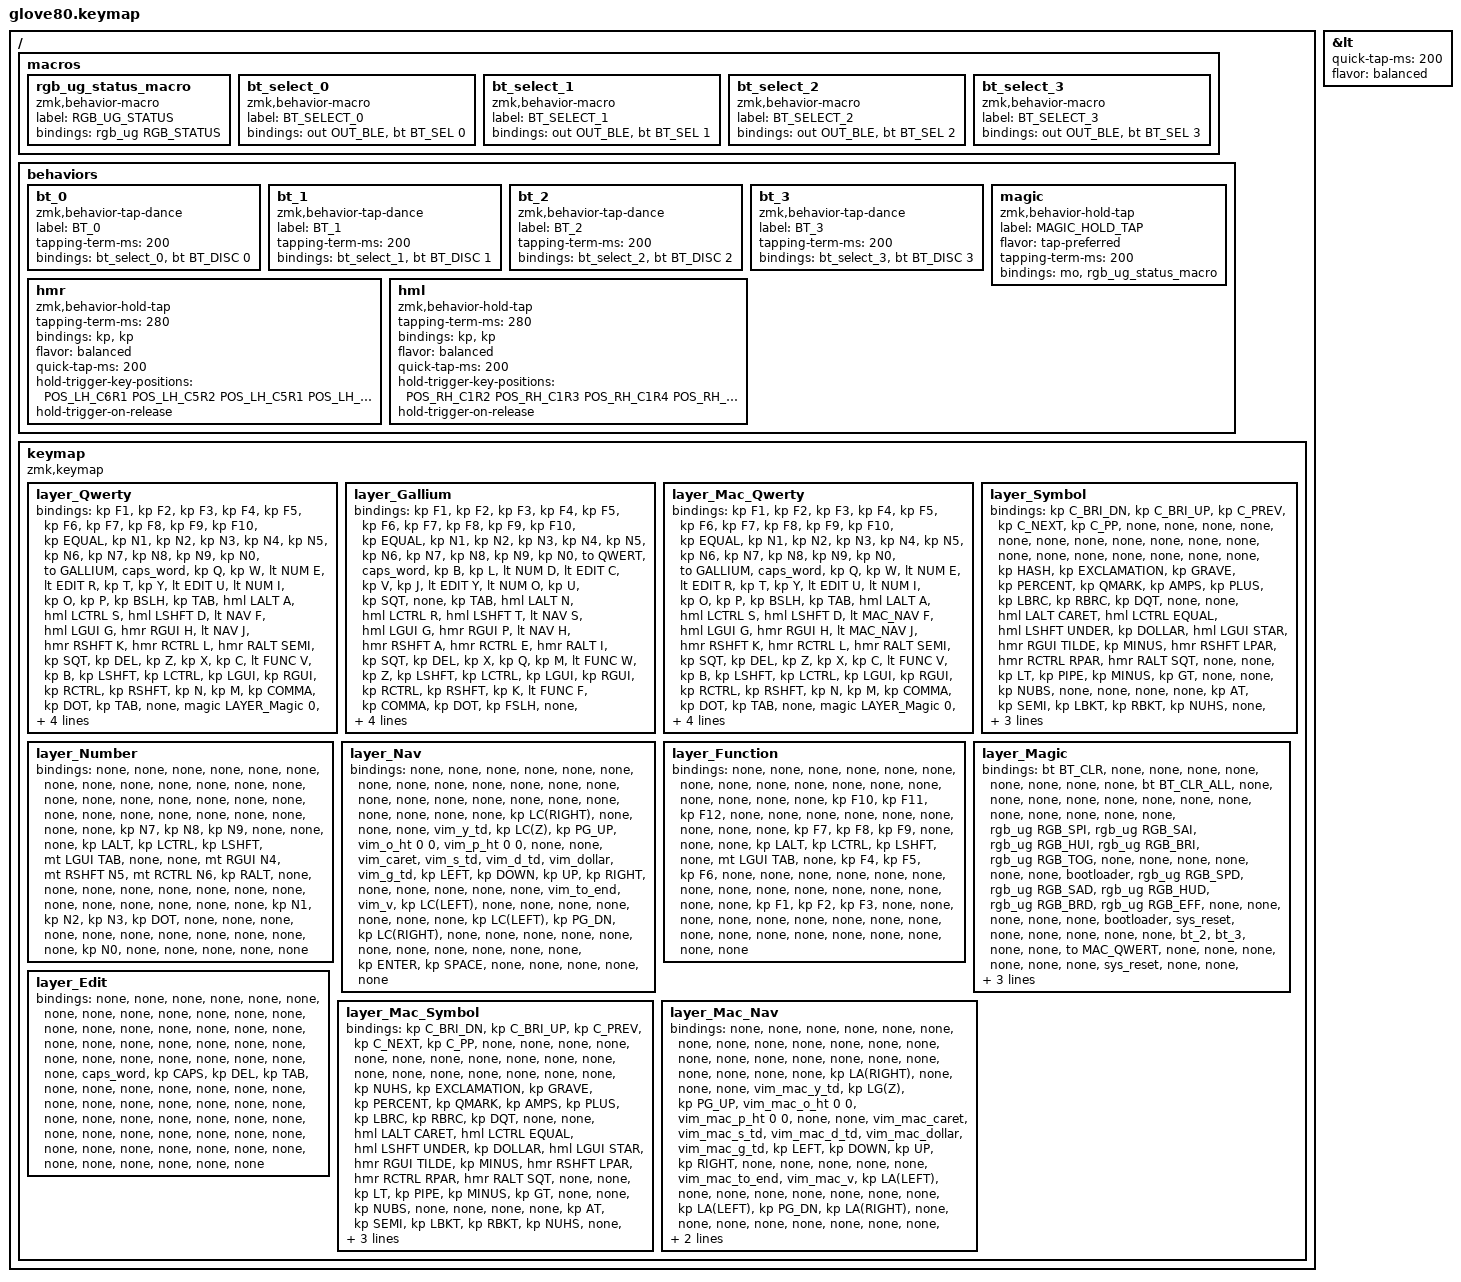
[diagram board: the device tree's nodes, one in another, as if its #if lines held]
#include <behaviors.dtsi>
/* Include all behavior includes needed */
#include <dt-bindings/zmk/outputs.h>
#include <dt-bindings/zmk/keys.h>
#include <dt-bindings/zmk/bt.h>
#include <dt-bindings/zmk/rgb.h>

/* Helper Macros, based on https://github.com/urob/zmk-helpers/ */

#pragma once

#define ZMK_HELPER_STRINGIFY(x) #x

// Preprocessor mechanism to overload macros, cf. https://stackoverflow.com/a/27051616/6114651
#define VARGS_(_10, _9, _8, _7, _6, _5, _4, _3, _2, _1, N, ...) N
#define VARGS(...) VARGS_(__VA_ARGS__, 10, 9, 8, 7, 6, 5, 4, 3, 2, 1, 0)
#define CONCAT_(a, b) a##b
#define CONCAT(a, b) CONCAT_(a, b)

#define ZMK_BEHAVIOR_CORE_tap_dance  \
    compatible = "zmk,behavior-tap-dance"; \
    #binding-cells = <0>

#define ZMK_BEHAVIOR(name, type, ...) \
    name: name { \
        ZMK_BEHAVIOR_CORE_ ## type; \
        __VA_ARGS__ \
    };

#define ZMK_TAP_DANCE(name, ...) \
    ZMK_BEHAVIOR(name, tap_dance, __VA_ARGS__)

#define ZMK_TD_LAYER(name, layer) \
    ZMK_TAP_DANCE(name, \
        tapping-term-ms = <200>; \
        bindings = <&mo layer>, <&to layer>; \
)

/* Automatically generated layer name defines */
#define QWERT 0
#define GALLIUM 1
#define MAC_QWERT 2
#define SYM 3
#define NUM 4
#define NAV 5
#define FUNC 6
#define LAYER_Magic 7
#define EDIT 8
#define MAC_SYM 9
#define MAC_NAV 10

/* Custom Device-tree */


/* Input Listeners */

/ {
    macros {
        rgb_ug_status_macro: rgb_ug_status_macro {
            label = "RGB_UG_STATUS";
            compatible = "zmk,behavior-macro";
            #binding-cells = <0>;
            bindings
                = <&rgb_ug RGB_STATUS>;
        };
    };
};


/ {
#ifdef BT_DISC_CMD
    behaviors {
        bt_0: bt_0 {
            compatible = "zmk,behavior-tap-dance";
            label = "BT_0";
            #binding-cells = <0>;
            tapping-term-ms = <200>;
            bindings = <&bt_select_0>, <&bt BT_DISC 0>;
        };
        bt_1: bt_1 {
            compatible = "zmk,behavior-tap-dance";
            label = "BT_1";
            #binding-cells = <0>;
            tapping-term-ms = <200>;
            bindings = <&bt_select_1>, <&bt BT_DISC 1>;
        };
        bt_2: bt_2 {
            compatible = "zmk,behavior-tap-dance";
            label = "BT_2";
            #binding-cells = <0>;
            tapping-term-ms = <200>;
            bindings = <&bt_select_2>, <&bt BT_DISC 2>;
        };
        bt_3: bt_3 {
            compatible = "zmk,behavior-tap-dance";
            label = "BT_3";
            #binding-cells = <0>;
            tapping-term-ms = <200>;
            bindings = <&bt_select_3>, <&bt BT_DISC 3>;
        };
    };
    macros {
        bt_select_0: bt_select_0 {
            label = "BT_SELECT_0";
            compatible = "zmk,behavior-macro";
            #binding-cells = <0>;
            bindings
                = <&out OUT_BLE>,
                  <&bt BT_SEL 0>;
        };
        bt_select_1: bt_select_1 {
            label = "BT_SELECT_1";
            compatible = "zmk,behavior-macro";
            #binding-cells = <0>;
            bindings
                = <&out OUT_BLE>,
                  <&bt BT_SEL 1>;
        };
        bt_select_2: bt_select_2 {
            label = "BT_SELECT_2";
            compatible = "zmk,behavior-macro";
            #binding-cells = <0>;
            bindings
                = <&out OUT_BLE>,
                  <&bt BT_SEL 2>;
        };
        bt_select_3: bt_select_3 {
            label = "BT_SELECT_3";
            compatible = "zmk,behavior-macro";
            #binding-cells = <0>;
            bindings
                = <&out OUT_BLE>,
                  <&bt BT_SEL 3>;
        };
    };
#else
    macros {
        bt_0: bt_0 {
            label = "BT_0";
            compatible = "zmk,behavior-macro";
            #binding-cells = <0>;
            bindings
                = <&out OUT_BLE>,
                  <&bt BT_SEL 0>;
        };
        bt_1: bt_1 {
            label = "BT_1";
            compatible = "zmk,behavior-macro";
            #binding-cells = <0>;
            bindings
                = <&out OUT_BLE>,
                  <&bt BT_SEL 1>;
        };
        bt_2: bt_2 {
            label = "BT_2";
            compatible = "zmk,behavior-macro";
            #binding-cells = <0>;
            bindings
                = <&out OUT_BLE>,
                  <&bt BT_SEL 2>;
        };
        bt_3: bt_3 {
            label = "BT_3";
            compatible = "zmk,behavior-macro";
            #binding-cells = <0>;
            bindings
                = <&out OUT_BLE>,
                  <&bt BT_SEL 3>;
        };
    };
#endif
};

/ {
    behaviors {
        magic: magic {
            compatible = "zmk,behavior-hold-tap";
            label = "MAGIC_HOLD_TAP";
            #binding-cells = <2>;
            flavor = "tap-preferred";
            tapping-term-ms = <200>;
            bindings = <&mo>, <&rgb_ug_status_macro>;
        };
    };
};


/* Key positions */

#define POS_LH_C6R1 0
#define POS_LH_C5R1 1
#define POS_LH_C4R1 2
#define POS_LH_C3R1 3
#define POS_LH_C2R1 4
#define POS_RH_C2R1 5
#define POS_RH_C3R1 6
#define POS_RH_C4R1 7
#define POS_RH_C5R1 8
#define POS_RH_C6R1 9
#define POS_LH_C6R2 10
#define POS_LH_C5R2 11
#define POS_LH_C4R2 12
#define POS_LH_C3R2 13
#define POS_LH_C2R2 14
#define POS_LH_C1R2 15
#define POS_RH_C1R2 16
#define POS_RH_C2R2 17
#define POS_RH_C3R2 18
#define POS_RH_C4R2 19
#define POS_RH_C5R2 20
#define POS_RH_C6R2 21
#define POS_LH_C6R3 22
#define POS_LH_C5R3 23
#define POS_LH_C4R3 24
#define POS_LH_C3R3 25
#define POS_LH_C2R3 26
#define POS_LH_C1R3 27
#define POS_RH_C1R3 28
#define POS_RH_C2R3 29
#define POS_RH_C3R3 30
#define POS_RH_C4R3 31
#define POS_RH_C5R3 32
#define POS_RH_C6R3 33
#define POS_LH_C6R4 34
#define POS_LH_C5R4 35
#define POS_LH_C4R4 36
#define POS_LH_C3R4 37
#define POS_LH_C2R4 38
#define POS_LH_C1R4 39
#define POS_RH_C1R4 40
#define POS_RH_C2R4 41
#define POS_RH_C3R4 42
#define POS_RH_C4R4 43
#define POS_RH_C5R4 44
#define POS_RH_C6R4 45
#define POS_LH_C6R5 46
#define POS_LH_C5R5 47
#define POS_LH_C4R5 48
#define POS_LH_C3R5 49
#define POS_LH_C2R5 50
#define POS_LH_C1R5 51
#define POS_LH_T1 52
#define POS_LH_T2 53
#define POS_LH_T3 54
#define POS_RH_T3 55
#define POS_RH_T2 56
#define POS_RH_T1 57
#define POS_RH_C1R5 58
#define POS_RH_C2R5 59
#define POS_RH_C3R5 60
#define POS_RH_C4R5 61
#define POS_RH_C5R5 62
#define POS_RH_C6R5 63
#define POS_LH_C6R6 64
#define POS_LH_C5R6 65
#define POS_LH_C4R6 66
#define POS_LH_C3R6 67
#define POS_LH_C2R6 68
#define POS_LH_T4 69
#define POS_LH_T5 70
#define POS_LH_T6 71
#define POS_RH_T6 72
#define POS_RH_T5 73
#define POS_RH_T4 74
#define POS_RH_C2R6 75
#define POS_RH_C3R6 76
#define POS_RH_C4R6 77
#define POS_RH_C5R6 78
#define POS_RH_C6R6 79

&lt {
    quick-tap-ms = <200>;
    flavor = "balanced";
};

/* Custom Defined Behaviors */
/ {

};

/* Generated input processors */


/* Automatically generated macro definitions */
/ {
    macros {

    };
};

/* Automatically generated behavior definitions */
/ {
    behaviors {

        // Right-hand HRMs
        hmr: hmr {
            compatible = "zmk,behavior-hold-tap";
            #binding-cells = <2>;
            tapping-term-ms = <280>;
            bindings = <&kp>, <&kp>;
            flavor = "balanced";
            quick-tap-ms = <200>;
            hold-trigger-key-positions = <POS_LH_C6R1 POS_LH_C5R2 POS_LH_C5R1 POS_LH_C4R2 POS_LH_C4R1 POS_LH_C4R3 POS_LH_C4R4 POS_LH_C4R6 POS_LH_C5R6 POS_LH_C5R5 POS_LH_C6R5 POS_LH_C6R6 POS_LH_C6R4 POS_LH_C5R4 POS_LH_C6R2 POS_LH_C5R3 POS_LH_C6R3 POS_LH_C4R5 POS_LH_C2R6 POS_LH_C2R5 POS_LH_C1R5 POS_LH_C2R4 POS_LH_C1R4 POS_LH_C3R4 POS_LH_C3R1 POS_LH_C2R1 POS_LH_C2R3 POS_LH_C1R3 POS_LH_C1R2 POS_LH_C2R2 POS_LH_C3R2 POS_LH_C3R3 POS_LH_C3R5 POS_LH_C3R6 POS_LH_T4 POS_LH_T6 POS_LH_T1 POS_LH_T5 POS_LH_T2 POS_LH_T3 POS_RH_T3 POS_RH_T1 POS_RH_T5 POS_RH_T2 POS_RH_T6 POS_RH_T4>;
            hold-trigger-on-release;
        };

        // Left-hand HRMs
        hml: hml {
            compatible = "zmk,behavior-hold-tap";
            #binding-cells = <2>;
            tapping-term-ms = <280>;
            bindings = <&kp>, <&kp>;
            flavor = "balanced";
            quick-tap-ms = <200>;
            hold-trigger-key-positions = <POS_RH_C1R2 POS_RH_C1R3 POS_RH_C1R4 POS_RH_C2R6 POS_RH_C1R5 POS_RH_C2R5 POS_RH_C2R1 POS_RH_C2R2 POS_RH_C2R3 POS_RH_C2R4 POS_RH_C3R4 POS_RH_C3R3 POS_RH_C3R2 POS_RH_C3R1 POS_RH_C4R1 POS_RH_C4R2 POS_RH_C4R3 POS_RH_C4R4 POS_RH_C4R5 POS_RH_C4R6 POS_RH_C3R6 POS_RH_C3R5 POS_RH_C5R6 POS_RH_C6R6 POS_RH_C6R5 POS_RH_C5R5 POS_RH_C5R4 POS_RH_C6R4 POS_RH_C6R3 POS_RH_C5R3 POS_RH_C5R2 POS_RH_C6R2 POS_RH_C6R1 POS_RH_C5R1 POS_RH_T3 POS_RH_T6 POS_RH_T5 POS_RH_T4 POS_RH_T1 POS_RH_T2 POS_LH_T3 POS_LH_T2 POS_LH_T6 POS_LH_T5 POS_LH_T4 POS_LH_T1>;
            hold-trigger-on-release;
        };
    };
};

#include "vim_macros.dtsi"

/* Automatically generated combos definitions */


/ {
    keymap {
        compatible = "zmk,keymap";


        layer_Qwerty {
            bindings = <
//    ┌────────────────────────┬─────────────┬─────────────┬─────────────┬───────────┐                                                                                                          ┌───────────┬─────────────┬─────────────┬─────────────┬────────────┐
//    │           f1           │     f2      │     f3      │     f4      │    f5     │                                                                                                          │    f6     │     f7      │     f8      │     f9      │    f10     │
//    ├────────────────────────┼─────────────┼─────────────┼─────────────┼───────────┼─────────────┐                                                                              ┌─────────────┼───────────┼─────────────┼─────────────┼─────────────┼────────────┤
//    │           =            │      1      │      2      │      3      │     4     │      5      │                                                                              │      6      │     7     │      8      │      9      │      0      │ to GALLIUM │
//    ├────────────────────────┼─────────────┼─────────────┼─────────────┼───────────┼─────────────┤                                                                              ├─────────────┼───────────┼─────────────┼─────────────┼─────────────┼────────────┤
//    │         capsw          │      Q      │      W      │  lt NUM E   │ lt EDIT R │      T      │                                                                              │      Y      │ lt EDIT U │  lt NUM I   │      O      │      P      │     \      │
//    ├────────────────────────┼─────────────┼─────────────┼─────────────┼───────────┼─────────────┤                                                                              ├─────────────┼───────────┼─────────────┼─────────────┼─────────────┼────────────┤
//    │          tab           │ &hml lalt A │ &hml lctl S │ &hml lsft D │ lt NAV F  │ &hml lgui G │                                                                              │ &hmr rgui H │ lt NAV J  │ &hmr rsft K │ &hmr rctl L │ &hmr ralt ; │     '      │
//    ├────────────────────────┼─────────────┼─────────────┼─────────────┼───────────┼─────────────┤   ┌─────────────┬────────────┬──────┐   ┌──────┬────────────┬────────────┐   ├─────────────┼───────────┼─────────────┼─────────────┼─────────────┼────────────┤
//    │          del           │      Z      │      X      │      C      │ lt FUNC V │      B      │   │    lsft     │    lctl    │ lgui │   │ rgui │    rctl    │    rsft    │   │      N      │     M     │      ,      │      .      │     tab     │            │
//    ├────────────────────────┼─────────────┼─────────────┼─────────────┼───────────┼─────────────┘   ├─────────────┼────────────┼──────┤   ├──────┼────────────┼────────────┤   └─────────────┼───────────┼─────────────┼─────────────┼─────────────┼────────────┤
//    │ &magic laltYER_Magic 0 │             │             │             │           │                 │ lt SYM bspc │ lt NUM esc │ del  │   │ ralt │ lt NUM ent │ lt SYM spc │                 │   left    │    down     │     up      │    rght     │    pscr    │
//    └────────────────────────┴─────────────┴─────────────┴─────────────┴───────────┘                 └─────────────┴────────────┴──────┘   └──────┴────────────┴────────────┘                 └───────────┴─────────────┴─────────────┴─────────────┴────────────┘
  &kp F1                 &kp F2        &kp F3         &kp F4         &kp F5                                                                                                                                &kp F6       &kp F7         &kp F8         &kp F9           &kp F10
  &kp EQUAL              &kp N1        &kp N2         &kp N3         &kp N4       &kp N5                                                                                                     &kp N6        &kp N7       &kp N8         &kp N9         &kp N0           &to GALLIUM
  &caps_word             &kp Q         &kp W          &lt NUM E      &lt EDIT R   &kp T                                                                                                      &kp Y         &lt EDIT U   &lt NUM I      &kp O          &kp P            &kp BSLH
  &kp TAB                &hml LALT A   &hml LCTRL S   &hml LSHFT D   &lt NAV F    &hml LGUI G                                                                                                &hmr RGUI H   &lt NAV J    &hmr RSHFT K   &hmr RCTRL L   &hmr RALT SEMI   &kp SQT
  &kp DEL                &kp Z         &kp X          &kp C          &lt FUNC V   &kp B             &kp LSHFT      &kp LCTRL     &kp LGUI       &kp RGUI   &kp RCTRL     &kp RSHFT           &kp N         &kp M        &kp COMMA      &kp DOT        &kp TAB          &none
  &magic LAYER_Magic 0   &none         &none          &none          &none                          &lt SYM BSPC   &lt NUM ESC   &kp DEL        &kp RALT   &lt NUM RET   &lt SYM SPACE                     &kp LEFT     &kp DOWN       &kp UP         &kp RIGHT        &kp PSCRN
            >;
        };



        layer_Gallium {
            bindings = <
//    ┌────────────────────────┬─────────────┬─────────────┬─────────────┬───────────┐                                                                                                          ┌───────────┬─────────────┬─────────────┬─────────────┬──────────┐
//    │           f1           │     f2      │     f3      │     f4      │    f5     │                                                                                                          │    f6     │     f7      │     f8      │     f9      │   f10    │
//    ├────────────────────────┼─────────────┼─────────────┼─────────────┼───────────┼─────────────┐                                                                              ┌─────────────┼───────────┼─────────────┼─────────────┼─────────────┼──────────┤
//    │           =            │      1      │      2      │      3      │     4     │      5      │                                                                              │      6      │     7     │      8      │      9      │      0      │ to QWERT │
//    ├────────────────────────┼─────────────┼─────────────┼─────────────┼───────────┼─────────────┤                                                                              ├─────────────┼───────────┼─────────────┼─────────────┼─────────────┼──────────┤
//    │         capsw          │      B      │      L      │  lt NUM D   │ lt EDIT C │      V      │                                                                              │      J      │ lt EDIT Y │  lt NUM O   │      U      │      '      │          │
//    ├────────────────────────┼─────────────┼─────────────┼─────────────┼───────────┼─────────────┤                                                                              ├─────────────┼───────────┼─────────────┼─────────────┼─────────────┼──────────┤
//    │          tab           │ &hml lalt N │ &hml lctl R │ &hml lsft T │ lt NAV S  │ &hml lgui G │                                                                              │ &hmr rgui P │ lt NAV H  │ &hmr rsft A │ &hmr rctl E │ &hmr ralt I │    '     │
//    ├────────────────────────┼─────────────┼─────────────┼─────────────┼───────────┼─────────────┤   ┌─────────────┬────────────┬──────┐   ┌──────┬────────────┬────────────┐   ├─────────────┼───────────┼─────────────┼─────────────┼─────────────┼──────────┤
//    │          del           │      X      │      Q      │      M      │ lt FUNC W │      Z      │   │    lsft     │    lctl    │ lgui │   │ rgui │    rctl    │    rsft    │   │      K      │ lt FUNC F │      ,      │      .      │      /      │          │
//    ├────────────────────────┼─────────────┼─────────────┼─────────────┼───────────┼─────────────┘   ├─────────────┼────────────┼──────┤   ├──────┼────────────┼────────────┤   └─────────────┼───────────┼─────────────┼─────────────┼─────────────┼──────────┤
//    │ &magic laltYER_Magic 0 │             │             │             │           │                 │ lt SYM bspc │ lt NUM esc │ del  │   │ ralt │ lt NUM ent │ lt SYM spc │                 │   left    │    down     │     up      │    rght     │   pscr   │
//    └────────────────────────┴─────────────┴─────────────┴─────────────┴───────────┘                 └─────────────┴────────────┴──────┘   └──────┴────────────┴────────────┘                 └───────────┴─────────────┴─────────────┴─────────────┴──────────┘
  &kp F1                 &kp F2        &kp F3         &kp F4         &kp F5                                                                                                                                &kp F6       &kp F7         &kp F8         &kp F9        &kp F10
  &kp EQUAL              &kp N1        &kp N2         &kp N3         &kp N4       &kp N5                                                                                                     &kp N6        &kp N7       &kp N8         &kp N9         &kp N0        &to QWERT
  &caps_word             &kp B         &kp L          &lt NUM D      &lt EDIT C   &kp V                                                                                                      &kp J         &lt EDIT Y   &lt NUM O      &kp U          &kp SQT       &none
  &kp TAB                &hml LALT N   &hml LCTRL R   &hml LSHFT T   &lt NAV S    &hml LGUI G                                                                                                &hmr RGUI P   &lt NAV H    &hmr RSHFT A   &hmr RCTRL E   &hmr RALT I   &kp SQT
  &kp DEL                &kp X         &kp Q          &kp M          &lt FUNC W   &kp Z             &kp LSHFT      &kp LCTRL     &kp LGUI       &kp RGUI   &kp RCTRL     &kp RSHFT           &kp K         &lt FUNC F   &kp COMMA      &kp DOT        &kp FSLH      &none
  &magic LAYER_Magic 0   &none         &none          &none          &none                          &lt SYM BSPC   &lt NUM ESC   &kp DEL        &kp RALT   &lt NUM RET   &lt SYM SPACE                     &kp LEFT     &kp DOWN       &kp UP         &kp RIGHT     &kp PSCRN
            >;
        };

        layer_Mac_Qwerty {
            bindings = <
//    ┌────────────────────────┬─────────────┬─────────────┬─────────────┬──────────────┐                                                                                                                  ┌──────────────┬─────────────┬─────────────┬─────────────┬────────────┐
//    │           f1           │     f2      │     f3      │     f4      │      f5      │                                                                                                                  │      f6      │     f7      │     f8      │     f9      │    f10     │
//    ├────────────────────────┼─────────────┼─────────────┼─────────────┼──────────────┼─────────────┐                                                                                      ┌─────────────┼──────────────┼─────────────┼─────────────┼─────────────┼────────────┤
//    │           =            │      1      │      2      │      3      │      4       │      5      │                                                                                      │      6      │      7       │      8      │      9      │      0      │ to GALLIUM │
//    ├────────────────────────┼─────────────┼─────────────┼─────────────┼──────────────┼─────────────┤                                                                                      ├─────────────┼──────────────┼─────────────┼─────────────┼─────────────┼────────────┤
//    │         capsw          │      Q      │      W      │  lt NUM E   │  lt EDIT R   │      T      │                                                                                      │      Y      │  lt EDIT U   │  lt NUM I   │      O      │      P      │     \      │
//    ├────────────────────────┼─────────────┼─────────────┼─────────────┼──────────────┼─────────────┤                                                                                      ├─────────────┼──────────────┼─────────────┼─────────────┼─────────────┼────────────┤
//    │          tab           │ &hml lalt A │ &hml lctl S │ &hml lsft D │ lt MAC_NAV F │ &hml lgui G │                                                                                      │ &hmr rgui H │ lt MAC_NAV J │ &hmr rsft K │ &hmr rctl L │ &hmr ralt ; │     '      │
//    ├────────────────────────┼─────────────┼─────────────┼─────────────┼──────────────┼─────────────┤   ┌─────────────────┬────────────┬──────┐   ┌──────┬────────────┬────────────────┐   ├─────────────┼──────────────┼─────────────┼─────────────┼─────────────┼────────────┤
//    │          del           │      Z      │      X      │      C      │  lt FUNC V   │      B      │   │      lsft       │    lctl    │ lgui │   │ rgui │    rctl    │      rsft      │   │      N      │      M       │      ,      │      .      │     tab     │            │
//    ├────────────────────────┼─────────────┼─────────────┼─────────────┼──────────────┼─────────────┘   ├─────────────────┼────────────┼──────┤   ├──────┼────────────┼────────────────┤   └─────────────┼──────────────┼─────────────┼─────────────┼─────────────┼────────────┤
//    │ &magic laltYER_Magic 0 │             │             │             │              │                 │ lt MAC_SYM bspc │ lt NUM esc │ del  │   │ ralt │ lt NUM ent │ lt MAC_SYM spc │                 │     left     │    down     │     up      │    rght     │    pscr    │
//    └────────────────────────┴─────────────┴─────────────┴─────────────┴──────────────┘                 └─────────────────┴────────────┴──────┘   └──────┴────────────┴────────────────┘                 └──────────────┴─────────────┴─────────────┴─────────────┴────────────┘
  &kp F1                 &kp F2        &kp F3         &kp F4         &kp F5                                                                                                                                           &kp F6          &kp F7         &kp F8         &kp F9           &kp F10
  &kp EQUAL              &kp N1        &kp N2         &kp N3         &kp N4          &kp N5                                                                                                             &kp N6        &kp N7          &kp N8         &kp N9         &kp N0           &to GALLIUM
  &caps_word             &kp Q         &kp W          &lt NUM E      &lt EDIT R      &kp T                                                                                                              &kp Y         &lt EDIT U      &lt NUM I      &kp O          &kp P            &kp BSLH
  &kp TAB                &hml LALT A   &hml LCTRL S   &hml LSHFT D   &lt MAC_NAV F   &hml LGUI G                                                                                                        &hmr RGUI H   &lt MAC_NAV J   &hmr RSHFT K   &hmr RCTRL L   &hmr RALT SEMI   &kp SQT
  &kp DEL                &kp Z         &kp X          &kp C          &lt FUNC V      &kp B             &kp LSHFT          &kp LCTRL     &kp LGUI       &kp RGUI   &kp RCTRL     &kp RSHFT               &kp N         &kp M           &kp COMMA      &kp DOT        &kp TAB          &none
  &magic LAYER_Magic 0   &none         &none          &none          &none                             &lt MAC_SYM BSPC   &lt NUM ESC   &kp DEL        &kp RALT   &lt NUM RET   &lt MAC_SYM SPACE                     &kp LEFT        &kp DOWN       &kp UP         &kp RIGHT        &kp PSCRN
            >;
        };

        layer_Symbol {
            bindings = <
//    ┌──────┬─────────────┬─────────────┬─────────────┬──────┐                                                                            ┌─────┬─────────────┬─────────────┬─────────────┬─────┐
//    │ bri- │    bri+     │    prev     │    next     │ play │                                                                            │     │             │             │             │     │
//    ├──────┼─────────────┼─────────────┼─────────────┼──────┼─────────────┐                                                ┌─────────────┼─────┼─────────────┼─────────────┼─────────────┼─────┤
//    │      │             │             │             │      │             │                                                │             │     │             │             │             │     │
//    ├──────┼─────────────┼─────────────┼─────────────┼──────┼─────────────┤                                                ├─────────────┼─────┼─────────────┼─────────────┼─────────────┼─────┤
//    │      │      #      │      !      │      `      │  %   │      ?      │                                                │      &      │  +  │      {      │      }      │      "      │     │
//    ├──────┼─────────────┼─────────────┼─────────────┼──────┼─────────────┤                                                ├─────────────┼─────┼─────────────┼─────────────┼─────────────┼─────┤
//    │      │ &hml lalt ^ │ &hml lctl = │ &hml lsft _ │  $   │ &hml lgui * │                                                │ &hmr rgui ~ │  -  │ &hmr rsft ( │ &hmr rctl ) │ &hmr ralt ' │     │
//    ├──────┼─────────────┼─────────────┼─────────────┼──────┼─────────────┤   ┌─────┬──────┬─────┐   ┌─────┬─────┬─────┐   ├─────────────┼─────┼─────────────┼─────────────┼─────────────┼─────┤
//    │      │      <      │      |      │      -      │  >   │             │   │     │ iso\ │     │   │     │     │     │   │      @      │  ;  │      [      │      ]      │    iso#     │     │
//    ├──────┼─────────────┼─────────────┼─────────────┼──────┼─────────────┘   ├─────┼──────┼─────┤   ├─────┼─────┼─────┤   └─────────────┼─────┼─────────────┼─────────────┼─────────────┼─────┤
//    │      │             │             │             │      │                 │  /  │  \   │     │   │     │ spc │  :  │                 │     │             │             │             │     │
//    └──────┴─────────────┴─────────────┴─────────────┴──────┘                 └─────┴──────┴─────┘   └─────┴─────┴─────┘                 └─────┴─────────────┴─────────────┴─────────────┴─────┘
  &kp C_BRI_DN   &kp C_BRI_UP      &kp C_PREV         &kp C_NEXT         &kp C_PP                                                                                                                   &none       &none             &none             &none           &none
  &none          &none             &none              &none              &none         &none                                                                                      &none             &none       &none             &none             &none           &none
  &none          &kp HASH          &kp EXCLAMATION    &kp GRAVE          &kp PERCENT   &kp QMARK                                                                                  &kp AMPS          &kp PLUS    &kp LBRC          &kp RBRC          &kp DQT         &none
  &none          &hml LALT CARET   &hml LCTRL EQUAL   &hml LSHFT UNDER   &kp DOLLAR    &hml LGUI STAR                                                                             &hmr RGUI TILDE   &kp MINUS   &hmr RSHFT LPAR   &hmr RCTRL RPAR   &hmr RALT SQT   &none
  &none          &kp LT            &kp PIPE           &kp MINUS          &kp GT        &none                &none      &kp NUBS   &none       &none   &none       &none           &kp AT            &kp SEMI    &kp LBKT          &kp RBKT          &kp NUHS        &none
  &none          &none             &none              &none              &none                              &kp FSLH   &kp BSLH   &none       &none   &kp SPACE   &kp COLON                         &none       &none             &none             &none           &none
            >;
        };





        layer_Number {
            bindings = <
//    ┌─────┬──────┬──────┬──────┬─────────────┐                                                           ┌───────────┬───────────┬───────────┬──────┬─────┐
//    │     │      │      │      │             │                                                           │           │           │           │      │     │
//    ├─────┼──────┼──────┼──────┼─────────────┼─────┐                                               ┌─────┼───────────┼───────────┼───────────┼──────┼─────┤
//    │     │      │      │      │             │     │                                               │     │           │           │           │      │     │
//    ├─────┼──────┼──────┼──────┼─────────────┼─────┤                                               ├─────┼───────────┼───────────┼───────────┼──────┼─────┤
//    │     │      │      │      │             │     │                                               │     │     7     │     8     │     9     │      │     │
//    ├─────┼──────┼──────┼──────┼─────────────┼─────┤                                               ├─────┼───────────┼───────────┼───────────┼──────┼─────┤
//    │     │ lalt │ lctl │ lsft │ mt lgui tab │     │                                               │     │ mt rgui 4 │ mt rsft 5 │ mt rctl 6 │ ralt │     │
//    ├─────┼──────┼──────┼──────┼─────────────┼─────┤   ┌─────┬─────┬─────┐   ┌─────┬─────┬─────┐   ├─────┼───────────┼───────────┼───────────┼──────┼─────┤
//    │     │      │      │      │             │     │   │     │     │     │   │     │     │     │   │     │     1     │     2     │     3     │  .   │     │
//    ├─────┼──────┼──────┼──────┼─────────────┼─────┘   ├─────┼─────┼─────┤   ├─────┼─────┼─────┤   └─────┼───────────┼───────────┼───────────┼──────┼─────┤
//    │     │      │      │      │             │         │     │     │     │   │     │     │  0  │         │           │           │           │      │     │
//    └─────┴──────┴──────┴──────┴─────────────┘         └─────┴─────┴─────┘   └─────┴─────┴─────┘         └───────────┴───────────┴───────────┴──────┴─────┘
  &none   &none      &none       &none       &none                                                                                       &none         &none          &none          &none      &none
  &none   &none      &none       &none       &none          &none                                                                &none   &none         &none          &none          &none      &none
  &none   &none      &none       &none       &none          &none                                                                &none   &kp N7        &kp N8         &kp N9         &none      &none
  &none   &kp LALT   &kp LCTRL   &kp LSHFT   &mt LGUI TAB   &none                                                                &none   &mt RGUI N4   &mt RSHFT N5   &mt RCTRL N6   &kp RALT   &none
  &none   &none      &none       &none       &none          &none       &none   &none   &none       &none   &none   &none        &none   &kp N1        &kp N2         &kp N3         &kp DOT    &none
  &none   &none      &none       &none       &none                      &none   &none   &none       &none   &none   &kp N0               &none         &none          &none          &none      &none
            >;
        };




        layer_Nav {
            bindings = <
//    ┌─────┬────────────┬────────────┬─────────────┬─────────────┐                                                                        ┌────────────┬──────┬───────────────┬───────────────┬─────┐
//    │     │            │            │             │             │                                                                        │            │      │               │               │     │
//    ├─────┼────────────┼────────────┼─────────────┼─────────────┼────────────┐                                               ┌───────────┼────────────┼──────┼───────────────┼───────────────┼─────┤
//    │     │            │            │             │             │            │                                               │           │            │      │               │               │     │
//    ├─────┼────────────┼────────────┼─────────────┼─────────────┼────────────┤                                               ├───────────┼────────────┼──────┼───────────────┼───────────────┼─────┤
//    │     │            │ lctl(rght) │             │             │            │                                               │ &vim_y_td │  lctl(Z)   │ pgup │ &vim_o_ht 0 0 │ &vim_p_ht 0 0 │     │
//    ├─────┼────────────┼────────────┼─────────────┼─────────────┼────────────┤                                               ├───────────┼────────────┼──────┼───────────────┼───────────────┼─────┤
//    │     │ &vim_caret │ &vim_s_td  │  &vim_d_td  │ &vim_dollar │ &vim_g_td  │                                               │   left    │    down    │  up  │     rght      │               │     │
//    ├─────┼────────────┼────────────┼─────────────┼─────────────┼────────────┤   ┌─────┬─────┬─────┐   ┌─────┬─────┬─────┐   ├───────────┼────────────┼──────┼───────────────┼───────────────┼─────┤
//    │     │            │            │ &vim_to_end │   &vim_v    │ lctl(left) │   │     │     │     │   │     │     │     │   │           │ lctl(left) │ pgdn │  lctl(rght)   │               │     │
//    ├─────┼────────────┼────────────┼─────────────┼─────────────┼────────────┘   ├─────┼─────┼─────┤   ├─────┼─────┼─────┤   └───────────┼────────────┼──────┼───────────────┼───────────────┼─────┤
//    │     │            │            │             │             │                │     │     │     │   │     │ ent │ spc │               │            │      │               │               │     │
//    └─────┴────────────┴────────────┴─────────────┴─────────────┘                └─────┴─────┴─────┘   └─────┴─────┴─────┘               └────────────┴──────┴───────────────┴───────────────┴─────┘
  &none   &none        &none           &none         &none                                                                                                        &none          &none       &none           &none           &none
  &none   &none        &none           &none         &none         &none                                                                              &none       &none          &none       &none           &none           &none
  &none   &none        &kp LC(RIGHT)   &none         &none         &none                                                                              &vim_y_td   &kp LC(Z)      &kp PG_UP   &vim_o_ht 0 0   &vim_p_ht 0 0   &none
  &none   &vim_caret   &vim_s_td       &vim_d_td     &vim_dollar   &vim_g_td                                                                          &kp LEFT    &kp DOWN       &kp UP      &kp RIGHT       &none           &none
  &none   &none        &none           &vim_to_end   &vim_v        &kp LC(LEFT)       &none   &none   &none       &none   &none       &none           &none       &kp LC(LEFT)   &kp PG_DN   &kp LC(RIGHT)   &none           &none
  &none   &none        &none           &none         &none                            &none   &none   &none       &none   &kp ENTER   &kp SPACE                   &none          &none       &none           &none           &none
            >;
        };




        layer_Function {
            bindings = <
//    ┌─────┬──────┬──────┬──────┬─────┐                                                                   ┌─────┬─────┬─────┬─────┬─────┐
//    │     │      │      │      │     │                                                                   │     │     │     │     │     │
//    ├─────┼──────┼──────┼──────┼─────┼─────────────┐                                               ┌─────┼─────┼─────┼─────┼─────┼─────┤
//    │     │      │      │      │     │             │                                               │     │ f10 │ f11 │ f12 │     │     │
//    ├─────┼──────┼──────┼──────┼─────┼─────────────┤                                               ├─────┼─────┼─────┼─────┼─────┼─────┤
//    │     │      │      │      │     │             │                                               │     │ f7  │ f8  │ f9  │     │     │
//    ├─────┼──────┼──────┼──────┼─────┼─────────────┤                                               ├─────┼─────┼─────┼─────┼─────┼─────┤
//    │     │ lalt │ lctl │ lsft │     │ mt lgui tab │                                               │     │ f4  │ f5  │ f6  │     │     │
//    ├─────┼──────┼──────┼──────┼─────┼─────────────┤   ┌─────┬─────┬─────┐   ┌─────┬─────┬─────┐   ├─────┼─────┼─────┼─────┼─────┼─────┤
//    │     │      │      │      │     │             │   │     │     │     │   │     │     │     │   │     │ f1  │ f2  │ f3  │     │     │
//    ├─────┼──────┼──────┼──────┼─────┼─────────────┘   ├─────┼─────┼─────┤   ├─────┼─────┼─────┤   └─────┼─────┼─────┼─────┼─────┼─────┤
//    │     │      │      │      │     │                 │     │     │     │   │     │     │     │         │     │     │     │     │     │
//    └─────┴──────┴──────┴──────┴─────┘                 └─────┴─────┴─────┘   └─────┴─────┴─────┘         └─────┴─────┴─────┴─────┴─────┘
  &none   &none      &none       &none       &none                                                                                      &none     &none     &none     &none   &none
  &none   &none      &none       &none       &none   &none                                                                      &none   &kp F10   &kp F11   &kp F12   &none   &none
  &none   &none      &none       &none       &none   &none                                                                      &none   &kp F7    &kp F8    &kp F9    &none   &none
  &none   &kp LALT   &kp LCTRL   &kp LSHFT   &none   &mt LGUI TAB                                                               &none   &kp F4    &kp F5    &kp F6    &none   &none
  &none   &none      &none       &none       &none   &none              &none   &none   &none       &none   &none   &none       &none   &kp F1    &kp F2    &kp F3    &none   &none
  &none   &none      &none       &none       &none                      &none   &none   &none       &none   &none   &none               &none     &none     &none     &none   &none
            >;
        };




        layer_Magic {
            bindings = <
//    ┌────────────┬─────────┬─────────┬─────────┬─────────┐                                                                                        ┌─────┬─────┬─────┬─────┬────────────┐
//    │   bt_clr   │         │         │         │         │                                                                                        │     │     │     │     │ bt_clr_ALL │
//    ├────────────┼─────────┼─────────┼─────────┼─────────┼─────────┐                                                                        ┌─────┼─────┼─────┼─────┼─────┼────────────┤
//    │            │         │         │         │         │         │                                                                        │     │     │     │     │     │            │
//    ├────────────┼─────────┼─────────┼─────────┼─────────┼─────────┤                                                                        ├─────┼─────┼─────┼─────┼─────┼────────────┤
//    │            │ ug_ sp+ │ ug_ sa+ │ ug_ hu+ │ ug_ br+ │ ug_ tog │                                                                        │     │     │     │     │     │            │
//    ├────────────┼─────────┼─────────┼─────────┼─────────┼─────────┤                                                                        ├─────┼─────┼─────┼─────┼─────┼────────────┤
//    │    boot    │ ug_ sp- │ ug_ sa- │ ug_ hu- │ ug_ br- │ ug_ eff │                                                                        │     │     │     │     │     │    boot    │
//    ├────────────┼─────────┼─────────┼─────────┼─────────┼─────────┤   ┌───────┬───────┬──────────┐   ┌─────┬──────────────┬────────────┐   ├─────┼─────┼─────┼─────┼─────┼────────────┤
//    │ &sys_reset │         │         │         │         │         │   │ &bt_2 │ &bt_3 │          │   │     │ to MAC_QWERT │            │   │     │     │     │     │     │ &sys_reset │
//    ├────────────┼─────────┼─────────┼─────────┼─────────┼─────────┘   ├───────┼───────┼──────────┤   ├─────┼──────────────┼────────────┤   └─────┼─────┼─────┼─────┼─────┼────────────┤
//    │            │         │         │         │         │             │ &bt_0 │ &bt_1 │ out_ usb │   │     │   to QWERT   │ to GALLIUM │         │     │     │     │     │            │
//    └────────────┴─────────┴─────────┴─────────┴─────────┘             └───────┴───────┴──────────┘   └─────┴──────────────┴────────────┘         └─────┴─────┴─────┴─────┴────────────┘
  &bt BT_CLR    &none             &none             &none             &none                                                                                                                        &none   &none   &none   &none   &bt BT_CLR_ALL
  &none         &none             &none             &none             &none             &none                                                                                              &none   &none   &none   &none   &none   &none
  &none         &rgb_ug RGB_SPI   &rgb_ug RGB_SAI   &rgb_ug RGB_HUI   &rgb_ug RGB_BRI   &rgb_ug RGB_TOG                                                                                    &none   &none   &none   &none   &none   &none
  &bootloader   &rgb_ug RGB_SPD   &rgb_ug RGB_SAD   &rgb_ug RGB_HUD   &rgb_ug RGB_BRD   &rgb_ug RGB_EFF                                                                                    &none   &none   &none   &none   &none   &bootloader
  &sys_reset    &none             &none             &none             &none             &none                 &bt_2   &bt_3   &none              &none   &to MAC_QWERT   &none             &none   &none   &none   &none   &none   &sys_reset
  &none         &none             &none             &none             &none                                   &bt_0   &bt_1   &out OUT_USB       &none   &to QWERT       &to GALLIUM               &none   &none   &none   &none   &none
            >;
        };

        layer_Edit {
            bindings = <
//    ┌─────┬───────┬──────┬─────┬─────┐                                                           ┌─────┬─────┬─────┬─────┬─────┐
//    │     │       │      │     │     │                                                           │     │     │     │     │     │
//    ├─────┼───────┼──────┼─────┼─────┼─────┐                                               ┌─────┼─────┼─────┼─────┼─────┼─────┤
//    │     │       │      │     │     │     │                                               │     │     │     │     │     │     │
//    ├─────┼───────┼──────┼─────┼─────┼─────┤                                               ├─────┼─────┼─────┼─────┼─────┼─────┤
//    │     │       │      │     │     │     │                                               │     │     │     │     │     │     │
//    ├─────┼───────┼──────┼─────┼─────┼─────┤                                               ├─────┼─────┼─────┼─────┼─────┼─────┤
//    │     │ capsw │ caps │ del │ tab │     │                                               │     │     │     │     │     │     │
//    ├─────┼───────┼──────┼─────┼─────┼─────┤   ┌─────┬─────┬─────┐   ┌─────┬─────┬─────┐   ├─────┼─────┼─────┼─────┼─────┼─────┤
//    │     │       │      │     │     │     │   │     │     │     │   │     │     │     │   │     │     │     │     │     │     │
//    ├─────┼───────┼──────┼─────┼─────┼─────┘   ├─────┼─────┼─────┤   ├─────┼─────┼─────┤   └─────┼─────┼─────┼─────┼─────┼─────┤
//    │     │       │      │     │     │         │     │     │     │   │     │     │     │         │     │     │     │     │     │
//    └─────┴───────┴──────┴─────┴─────┘         └─────┴─────┴─────┘   └─────┴─────┴─────┘         └─────┴─────┴─────┴─────┴─────┘
  &none   &none        &none      &none     &none                                                                                 &none   &none   &none   &none   &none
  &none   &none        &none      &none     &none     &none                                                               &none   &none   &none   &none   &none   &none
  &none   &none        &none      &none     &none     &none                                                               &none   &none   &none   &none   &none   &none
  &none   &caps_word   &kp CAPS   &kp DEL   &kp TAB   &none                                                               &none   &none   &none   &none   &none   &none
  &none   &none        &none      &none     &none     &none       &none   &none   &none       &none   &none   &none       &none   &none   &none   &none   &none   &none
  &none   &none        &none      &none     &none                 &none   &none   &none       &none   &none   &none               &none   &none   &none   &none   &none
            >;
        };


        layer_Mac_Symbol {
            bindings = <
//    ┌──────┬─────────────┬─────────────┬─────────────┬──────┐                                                                            ┌─────┬─────────────┬─────────────┬─────────────┬─────┐
//    │ bri- │    bri+     │    prev     │    next     │ play │                                                                            │     │             │             │             │     │
//    ├──────┼─────────────┼─────────────┼─────────────┼──────┼─────────────┐                                                ┌─────────────┼─────┼─────────────┼─────────────┼─────────────┼─────┤
//    │      │             │             │             │      │             │                                                │             │     │             │             │             │     │
//    ├──────┼─────────────┼─────────────┼─────────────┼──────┼─────────────┤                                                ├─────────────┼─────┼─────────────┼─────────────┼─────────────┼─────┤
//    │      │    iso#     │      !      │      `      │  %   │      ?      │                                                │      &      │  +  │      {      │      }      │      "      │     │
//    ├──────┼─────────────┼─────────────┼─────────────┼──────┼─────────────┤                                                ├─────────────┼─────┼─────────────┼─────────────┼─────────────┼─────┤
//    │      │ &hml lalt ^ │ &hml lctl = │ &hml lsft _ │  $   │ &hml lgui * │                                                │ &hmr rgui ~ │  -  │ &hmr rsft ( │ &hmr rctl ) │ &hmr ralt ' │     │
//    ├──────┼─────────────┼─────────────┼─────────────┼──────┼─────────────┤   ┌─────┬──────┬─────┐   ┌─────┬─────┬─────┐   ├─────────────┼─────┼─────────────┼─────────────┼─────────────┼─────┤
//    │      │      <      │      |      │      -      │  >   │             │   │     │ iso\ │     │   │     │     │     │   │      @      │  ;  │      [      │      ]      │    iso#     │     │
//    ├──────┼─────────────┼─────────────┼─────────────┼──────┼─────────────┘   ├─────┼──────┼─────┤   ├─────┼─────┼─────┤   └─────────────┼─────┼─────────────┼─────────────┼─────────────┼─────┤
//    │      │             │             │             │      │                 │  /  │  \   │     │   │     │ spc │  :  │                 │     │             │             │             │     │
//    └──────┴─────────────┴─────────────┴─────────────┴──────┘                 └─────┴──────┴─────┘   └─────┴─────┴─────┘                 └─────┴─────────────┴─────────────┴─────────────┴─────┘
  &kp C_BRI_DN   &kp C_BRI_UP      &kp C_PREV         &kp C_NEXT         &kp C_PP                                                                                                                   &none       &none             &none             &none           &none
  &none          &none             &none              &none              &none         &none                                                                                      &none             &none       &none             &none             &none           &none
  &none          &kp NUHS          &kp EXCLAMATION    &kp GRAVE          &kp PERCENT   &kp QMARK                                                                                  &kp AMPS          &kp PLUS    &kp LBRC          &kp RBRC          &kp DQT         &none
  &none          &hml LALT CARET   &hml LCTRL EQUAL   &hml LSHFT UNDER   &kp DOLLAR    &hml LGUI STAR                                                                             &hmr RGUI TILDE   &kp MINUS   &hmr RSHFT LPAR   &hmr RCTRL RPAR   &hmr RALT SQT   &none
  &none          &kp LT            &kp PIPE           &kp MINUS          &kp GT        &none                &none      &kp NUBS   &none       &none   &none       &none           &kp AT            &kp SEMI    &kp LBKT          &kp RBKT          &kp NUHS        &none
  &none          &none             &none              &none              &none                              &kp FSLH   &kp BSLH   &none       &none   &kp SPACE   &kp COLON                         &none       &none             &none             &none           &none
            >;
        };

        layer_Mac_Nav {
            bindings = <
//    ┌─────┬────────────────┬───────────────┬─────────────────┬─────────────────┐                                                                               ┌────────────┬──────┬───────────────────┬───────────────────┬─────┐
//    │     │                │               │                 │                 │                                                                               │            │      │                   │                   │     │
//    ├─────┼────────────────┼───────────────┼─────────────────┼─────────────────┼───────────────┐                                               ┌───────────────┼────────────┼──────┼───────────────────┼───────────────────┼─────┤
//    │     │                │               │                 │                 │               │                                               │               │            │      │                   │                   │     │
//    ├─────┼────────────────┼───────────────┼─────────────────┼─────────────────┼───────────────┤                                               ├───────────────┼────────────┼──────┼───────────────────┼───────────────────┼─────┤
//    │     │                │  lalt(rght)   │                 │                 │               │                                               │ &vim_mac_y_td │  lgui(Z)   │ pgup │ &vim_mac_o_ht 0 0 │ &vim_mac_p_ht 0 0 │     │
//    ├─────┼────────────────┼───────────────┼─────────────────┼─────────────────┼───────────────┤                                               ├───────────────┼────────────┼──────┼───────────────────┼───────────────────┼─────┤
//    │     │ &vim_mac_caret │ &vim_mac_s_td │  &vim_mac_d_td  │ &vim_mac_dollar │ &vim_mac_g_td │                                               │     left      │    down    │  up  │       rght        │                   │     │
//    ├─────┼────────────────┼───────────────┼─────────────────┼─────────────────┼───────────────┤   ┌─────┬─────┬─────┐   ┌─────┬─────┬─────┐   ├───────────────┼────────────┼──────┼───────────────────┼───────────────────┼─────┤
//    │     │                │               │ &vim_mac_to_end │   &vim_mac_v    │  lalt(left)   │   │     │     │     │   │     │     │     │   │               │ lalt(left) │ pgdn │    lalt(rght)     │                   │     │
//    ├─────┼────────────────┼───────────────┼─────────────────┼─────────────────┼───────────────┘   ├─────┼─────┼─────┤   ├─────┼─────┼─────┤   └───────────────┼────────────┼──────┼───────────────────┼───────────────────┼─────┤
//    │     │                │               │                 │                 │                   │     │     │     │   │     │ ent │ spc │                   │            │      │                   │                   │     │
//    └─────┴────────────────┴───────────────┴─────────────────┴─────────────────┘                   └─────┴─────┴─────┘   └─────┴─────┴─────┘                   └────────────┴──────┴───────────────────┴───────────────────┴─────┘
  &none   &none            &none           &none             &none                                                                                                                 &none          &none       &none               &none               &none
  &none   &none            &none           &none             &none             &none                                                                               &none           &none          &none       &none               &none               &none
  &none   &none            &kp LA(RIGHT)   &none             &none             &none                                                                               &vim_mac_y_td   &kp LG(Z)      &kp PG_UP   &vim_mac_o_ht 0 0   &vim_mac_p_ht 0 0   &none
  &none   &vim_mac_caret   &vim_mac_s_td   &vim_mac_d_td     &vim_mac_dollar   &vim_mac_g_td                                                                       &kp LEFT        &kp DOWN       &kp UP      &kp RIGHT           &none               &none
  &none   &none            &none           &vim_mac_to_end   &vim_mac_v        &kp LA(LEFT)        &none   &none   &none       &none   &none       &none           &none           &kp LA(LEFT)   &kp PG_DN   &kp LA(RIGHT)       &none               &none
  &none   &none            &none           &none             &none                                 &none   &none   &none       &none   &kp ENTER   &kp SPACE                       &none          &none       &none               &none               &none
            >;
        };

    };
};
